VERSION "IPC CAN 1.0"

NS_ :

BS_:

BU_: VCU_RPI ECU_UNO SWC_ESP32 IPC_HMI

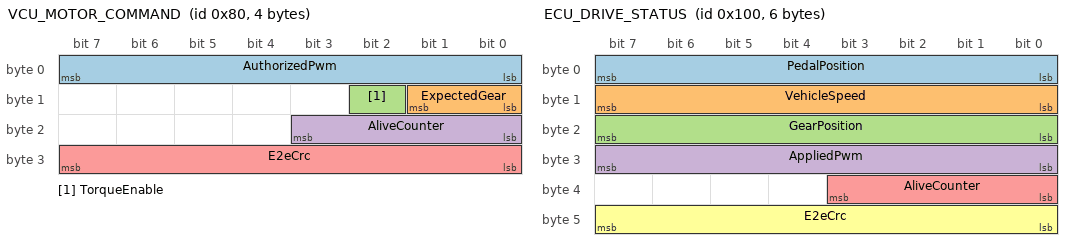
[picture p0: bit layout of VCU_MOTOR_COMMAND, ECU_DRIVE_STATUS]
BO_ 128 VCU_MOTOR_COMMAND: 4 VCU_RPI
 SG_ AuthorizedPwm : 0|8@1+ (1,0) [0|255] "pwm" ECU_UNO
 SG_ ExpectedGear : 8|2@1+ (1,0) [0|3] "" ECU_UNO
 SG_ TorqueEnable : 10|1@1+ (1,0) [0|1] "" ECU_UNO
 SG_ AliveCounter : 16|4@1+ (1,0) [0|15] "" ECU_UNO
 SG_ E2eCrc : 24|8@1+ (1,0) [0|255] "" ECU_UNO

BO_ 256 ECU_DRIVE_STATUS: 6 ECU_UNO
 SG_ PedalPosition : 0|8@1+ (1,0) [0|100] "%" VCU_RPI
 SG_ VehicleSpeed : 8|8@1+ (1,0) [0|255] "km/h" VCU_RPI
 SG_ GearPosition : 16|8@1+ (1,0) [0|3] "" VCU_RPI
 SG_ AppliedPwm : 24|8@1+ (1,0) [0|255] "pwm" VCU_RPI
 SG_ AliveCounter : 32|4@1+ (1,0) [0|15] "" VCU_RPI
 SG_ E2eCrc : 40|8@1+ (1,0) [0|255] "" VCU_RPI

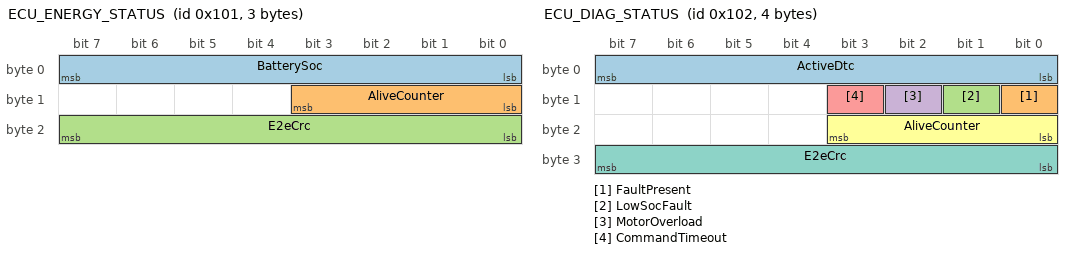
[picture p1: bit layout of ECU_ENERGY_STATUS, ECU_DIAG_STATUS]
BO_ 257 ECU_ENERGY_STATUS: 3 ECU_UNO
 SG_ BatterySoc : 0|8@1+ (1,0) [0|100] "%" VCU_RPI
 SG_ AliveCounter : 8|4@1+ (1,0) [0|15] "" VCU_RPI
 SG_ E2eCrc : 16|8@1+ (1,0) [0|255] "" VCU_RPI

BO_ 258 ECU_DIAG_STATUS: 4 ECU_UNO
 SG_ ActiveDtc : 0|8@1+ (1,0) [0|255] "" VCU_RPI
 SG_ FaultPresent : 8|1@1+ (1,0) [0|1] "" VCU_RPI
 SG_ LowSocFault : 9|1@1+ (1,0) [0|1] "" VCU_RPI
 SG_ MotorOverload : 10|1@1+ (1,0) [0|1] "" VCU_RPI
 SG_ CommandTimeout : 11|1@1+ (1,0) [0|1] "" VCU_RPI
 SG_ AliveCounter : 16|4@1+ (1,0) [0|15] "" VCU_RPI
 SG_ E2eCrc : 24|8@1+ (1,0) [0|255] "" VCU_RPI

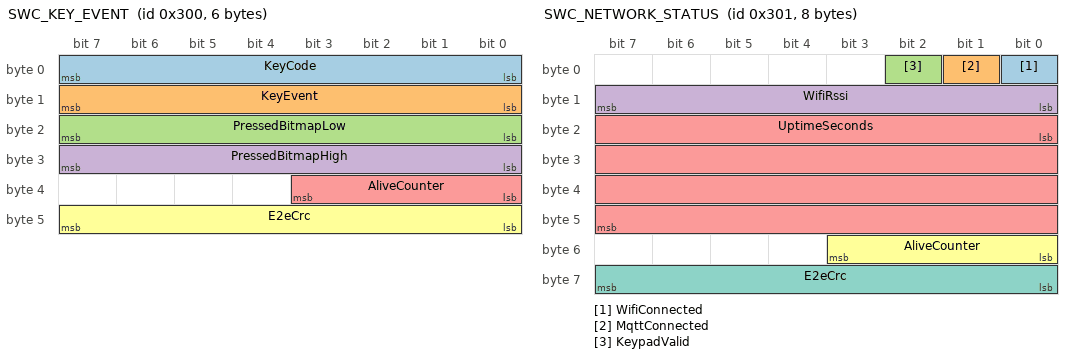
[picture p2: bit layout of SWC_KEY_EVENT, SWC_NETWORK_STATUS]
BO_ 768 SWC_KEY_EVENT: 6 SWC_ESP32
 SG_ KeyCode : 0|8@1+ (1,0) [0|15] "" VCU_RPI
 SG_ KeyEvent : 8|8@1+ (1,0) [0|2] "" VCU_RPI
 SG_ PressedBitmapLow : 16|8@1+ (1,0) [0|255] "" VCU_RPI
 SG_ PressedBitmapHigh : 24|8@1+ (1,0) [0|255] "" VCU_RPI
 SG_ AliveCounter : 32|4@1+ (1,0) [0|15] "" VCU_RPI
 SG_ E2eCrc : 40|8@1+ (1,0) [0|255] "" VCU_RPI

BO_ 769 SWC_NETWORK_STATUS: 8 SWC_ESP32
 SG_ WifiConnected : 0|1@1+ (1,0) [0|1] "" VCU_RPI
 SG_ MqttConnected : 1|1@1+ (1,0) [0|1] "" VCU_RPI
 SG_ KeypadValid : 2|1@1+ (1,0) [0|1] "" VCU_RPI
 SG_ WifiRssi : 8|8@1- (1,0) [-128|127] "dBm" VCU_RPI
 SG_ UptimeSeconds : 16|32@1+ (1,0) [0|4294967295] "s" VCU_RPI
 SG_ AliveCounter : 48|4@1+ (1,0) [0|15] "" VCU_RPI
 SG_ E2eCrc : 56|8@1+ (1,0) [0|255] "" VCU_RPI

VAL_ 128 ExpectedGear 0 "P" 1 "R" 2 "N" 3 "D";
VAL_ 256 GearPosition 0 "P" 1 "R" 2 "N" 3 "D";
VAL_ 768 KeyEvent 0 "Press" 1 "Release" 2 "LongPress";

CM_ "Project CAN contract. UART and MQTT are transports and do not change message payloads.";
CM_ BO_ 128 "Safety-critical motor authorization. Receiver timeout is 350 ms.";
